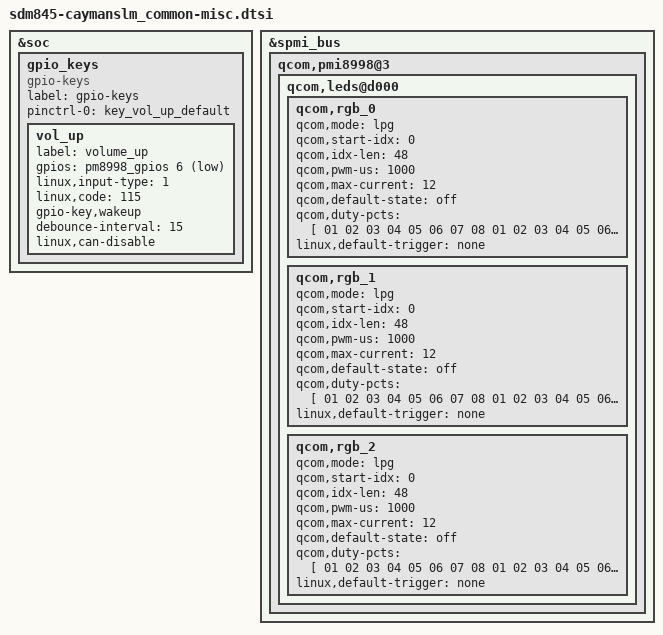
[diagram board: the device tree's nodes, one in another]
/* Copyright (c) 2017, The Linux Foundation. All rights reserved.
 *
 * This program is free software; you can redistribute it and/or modify
 * it under the terms of the GNU General Public License version 2 and
 * only version 2 as published by the Free Software Foundation.
 *
 * This program is distributed in the hope that it will be useful,
 * but WITHOUT ANY WARRANTY; without even the implied warranty of
 * MERCHANTABILITY or FITNESS FOR A PARTICULAR PURPOSE.  See the
 * GNU General Public License for more details.
 */

&soc {
	gpio_keys {
		compatible = "gpio-keys";
		label = "gpio-keys";
		status = "okay";

		pinctrl-names = "default";
		pinctrl-0 = <&key_vol_up_default>;

		vol_up {
			label = "volume_up";
			gpios = <&pm8998_gpios 6 GPIO_ACTIVE_LOW>;
			linux,input-type = <1>;
			linux,code = <115>;
			gpio-key,wakeup;
			debounce-interval = <15>;
			linux,can-disable;
		};
	};
};

/* LED setting */
 &spmi_bus {
	 qcom,pmi8998@3 {
		 qcom,leds@d000 {
			 status = "okay";
			 qcom,rgb_0 {
				 qcom,mode = "lpg";
				 qcom,start-idx = <0>;
				 qcom,idx-len = <48>;
				 qcom,pwm-us = <1000>;
				 qcom,max-current = <12>;
				 qcom,default-state = "off";
				 qcom,duty-pcts = [
                                          01 02 03 04 05 06 07 08
                                          01 02 03 04 05 06 07 08
                                          09 0A 0B 0C 0D 0E 0F 10
                                          09 0A 0B 0C 0D 0E 0F 10
					  11 12 13 14 15 16 17 18
					  11 12 13 14 15 16 17 18
				 ];
				 linux,default-trigger = "none";
			 };

			 qcom,rgb_1 {
				 qcom,mode = "lpg";
				 qcom,start-idx = <0>;
				 qcom,idx-len = <48>;
				 qcom,pwm-us = <1000>;
				 qcom,max-current = <12>;
				 qcom,default-state = "off";
				 qcom,duty-pcts = [
                                          01 02 03 04 05 06 07 08
                                          01 02 03 04 05 06 07 08
                                          09 0A 0B 0C 0D 0E 0F 10
                                          09 0A 0B 0C 0D 0E 0F 10
					  11 12 13 14 15 16 17 18
					  11 12 13 14 15 16 17 18
				 ];
				 linux,default-trigger = "none";
			 };

			 qcom,rgb_2 {
				 qcom,mode = "lpg";
				 qcom,start-idx = <0>;
				 qcom,idx-len = <48>;
				 qcom,pwm-us = <1000>;
				 qcom,max-current = <12>;
				 qcom,default-state = "off";
				 qcom,duty-pcts = [
                                          01 02 03 04 05 06 07 08
                                          01 02 03 04 05 06 07 08
                                          09 0A 0B 0C 0D 0E 0F 10
                                          09 0A 0B 0C 0D 0E 0F 10
					  11 12 13 14 15 16 17 18
					  11 12 13 14 15 16 17 18
				 ];
				 linux,default-trigger = "none";
			 };
		 };
	 };
 };

